# STM32U3C5 register map
File version: 1.0
CPU: CM33 r0p1, little endian, MPU, FPU, 4 interrupt priority bits
Registers are 32-bit, read-write, reset 0x0 unless marked. A register's access mark holds for its fields unless they carry their own. Offsets are from the block's base; [hi:lo] are bit positions; {n}, {i} and the like mark numbered series.

## SYSCFG — SYSCFG register block
Base 0x40040400
Same registers: SEC_SYSCFG 0x50040400
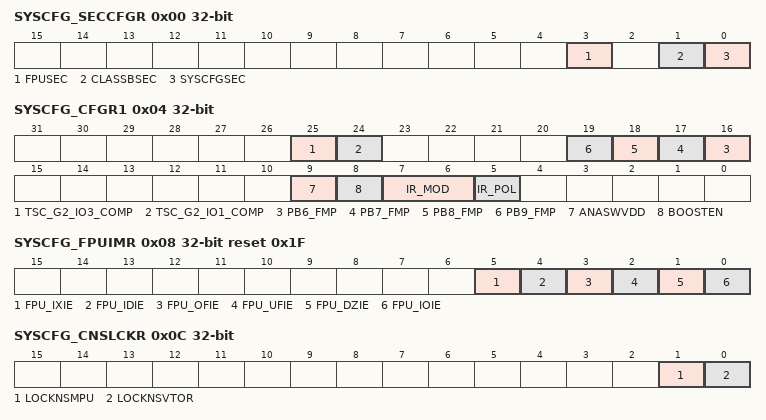
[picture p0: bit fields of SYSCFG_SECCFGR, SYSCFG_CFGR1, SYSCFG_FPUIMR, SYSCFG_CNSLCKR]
0x00 SYSCFG_SECCFGR — SYSCFG secure configuration register
  [3] FPUSEC — FPU security
    0=SYSCFG_FPUIMR can be read and written by secure and nonsecure access; 1=SYSCFG_FPUIMR can be read and written by secure access only
  [1] CLASSBSEC — Class B security
    0=SYSCFG_CFGR2 can be read and written by secure and nonsecure access; 1=SYSCFG_CFGR2 can be read and written by secure access only
  [0] SYSCFGSEC — Security of SYSCFG clock control, memory erase status, and compensation cell registers
    0=SYSCFG configuration clock in RCC registers and SYSCFG_CCCSR, SYSCFG_CCVR, and SYSCFG_CCCR can be read and written by secure and nonsecure access; 1=SYSCFG configuration clock in RCC registers and SYSCFG_CCCSR, SYSCFG_CCVR, and SYSCFG_CCCR can be read and written by secure access only
0x04 SYSCFG_CFGR1 — SYSCFG configuration register 1
  [25] TSC_G2_IO3_COMP — Comparator mode for G2_IO3 on PB6
    0=Normal mode: TSC_G2_IO3 detection is done using PB6 Vless thansub>IHless than/sub> I/O threshold; 1=Comparator mode: TSC_G2_IO3 detection is done using COMP2_INM threshold
  [24] TSC_G2_IO1_COMP — Comparator mode for G2_IO1 on PB4
    0=Normal mode: TSC_G2_IO1 detection is done using PB4 Vless thansub>IHless than/sub> I/O threshold; 1=Comparator mode: TSC_G2_IO1 detection is done using COMP2_INM threshold
  [n+10] PB{n}_FMP (n=6..9) — Fast-mode Plus driving capability activation on PBi
    0=PBi pin operates in standard mode; 1=Fm+ mode is enabled on PBi pin and the speed control is bypassed
  [9] ANASWVDD — GPIO analog switch control voltage selection
    0=I/O analog switches are supplied by Vless thansub>DDAless than/sub> or booster when booster is ON; 1=I/O analog switches are supplied by Vless thansub>DDless than/sub>
  [8] BOOSTEN — I/O analog switch voltage booster enable
    0=I/O analog switches are supplied by Vless thansub>DDAless than/sub> voltage; 1=I/O analog switches are supplied by a dedicated voltage booster (supplied by Vless thansub>DDless than/sub>)
  [7:6] IR_MOD — IR modulation envelope signal selection
    0=TIM16; 1=USART1; 2=UART4
  [5] IR_POL — IR output polarity selection
    0=Output of IRTIM (IR_OUT) is not inverted; 1=Output of IRTIM (IR_OUT) is inverted
0x08 SYSCFG_FPUIMR reset 0x1F — SYSCFG FPU interrupt mask register
  [all] fields
    0=Interrupt disabled; 1=Interrupt enabled
  [5] FPU_IXIE — Floating point unit interrupt enable bit - inexact
  [4] FPU_IDIE — Floating point unit interrupt enable bit - input denormal
  [3] FPU_OFIE — Floating point unit interrupt enable bit - overflow
  [2] FPU_UFIE — Floating point unit interrupt enable bit - underflow
  [1] FPU_DZIE — Floating point unit interrupt enable bit - divide-by-zero
  [0] FPU_IOIE — Floating point unit interrupt enable bit - invalid operation
0x0C SYSCFG_CNSLCKR — SYSCFG CPU nonsecure lock register
  [1] LOCKNSMPU — Nonsecure MPU registers lock
    0=Nonsecure MPU register write enabled; 1=Nonsecure MPU register write disabled
  [0] LOCKNSVTOR — VTOR_NS register lock
    0=VTOR_NS register write enabled; 1=VTOR_NS register write disabled
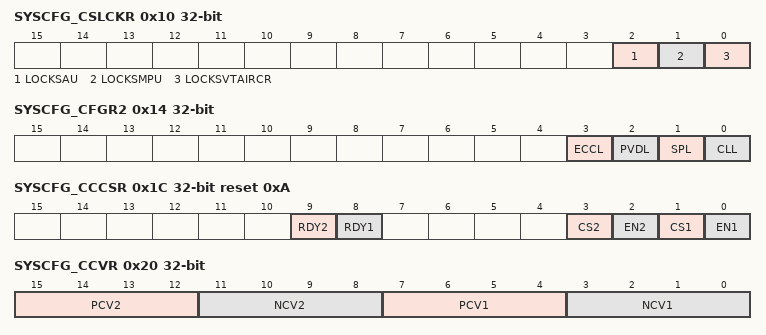
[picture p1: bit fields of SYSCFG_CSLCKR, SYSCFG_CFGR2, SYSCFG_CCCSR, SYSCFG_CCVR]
0x10 SYSCFG_CSLCKR — SYSCFG CPU secure lock register
  [2] LOCKSAU — SAU register lock
    0=SAU register write enabled; 1=SAU register write disabled
  [1] LOCKSMPU — Secure MPU registers lock
    0=Secure MPU register writes enabled; 1=Secure MPU register writes disabled
  [0] LOCKSVTAIRCR — VTOR_S register and AIRCR register bits lock
    0=VTOR_S register PRIS and BFHFNMINS bits in AIRCR register write enabled; 1=VTOR_S register PRIS and BFHFNMINS bits in AIRCR register write disabled
0x14 SYSCFG_CFGR2 — SYSCFG configuration register 2
  [3] ECCL — ECC lock
    0=ECC double error disconnected from TIM1/8/15/16/17 break input; 1=ECC double error connected to TIM1/8/15/16/17 break input
  [2] PVDL — PVD lock enable bit
    0=PVD interrupt disconnected from TIM1/8/15/16/17 break input; 1=PVD interrupt connected to TIM1/8/15/16/17 break input
  [1] SPL — SRAM2 parity bit
    0=SRAM double error disconnected from TIM1/8/15/16/17 break inputs; 1=SRAM double error connected to TIM1/8/15/16/17 break inputs
  [0] CLL — Cortex-M33 LOCKUP (HardFault) output enable
    0=Cortex-M33 LOCKUP output disconnected from TIM1/8/15/16/17 break inputs; 1=Cortex-M33 LOCKUP output connected to TIM1/8/15/16/17 break inputs
0x1C SYSCFG_CCCSR reset 0xA — SYSCFG compensation cell control/status register
  [9] RDY2 ro — VDDIO2 I/O compensation cell ready flag
    0=VDDIO2 I/O compensation cell not ready; 1=VDDIO2 I/O compensation cell ready
  [8] RDY1 ro — VDD I/O compensation cell ready flag
    0=VDD I/O compensation cell not ready; 1=VDD I/O compensation cell ready
  [3] CS2 — VDDIO2 I/O code selection
    0=VDDIO2 I/O code from the cell (available in SYSCFG_CCVR); 1=VDDIO2 I/O code from SYSCFG_CCCR
  [2] EN2 — VDDIO2 I/O compensation cell enable
    0=VDDIO2 I/O compensation cell disabled; 1=VDDIO2 I/O compensation cell enabled
  [1] CS1 — VDD I/O code selection
    0=VDD I/O code from the cell (available in the SYSCFG_CCVR); 1=VDD I/O code from the SYSCFG compensation cell code register (SYSCFG_CCCR)
  [0] EN1 — VDD I/O compensation cell enable
    0=VDD I/O compensation cell disabled; 1=VDD I/O compensation cell enabled
0x20 SYSCFG_CCVR ro — SYSCFG compensation cell value register
  [15:12] PCV2 — PMOS compensation value of the I/Os supplied by Vless thansub>DDIO2less than/sub>
  [11:8] NCV2 — NMOS compensation value of the I/Os supplied by Vless thansub>DDIO2less than/sub>
  [7:4] PCV1 — PMOS compensation value of the I/Os supplied by Vless thansub>DDless than/sub>
  [3:0] NCV1 — NMOS compensation value of the I/Os supplied by Vless thansub>DDless than/sub>
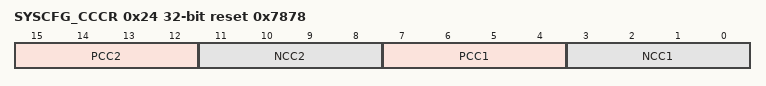
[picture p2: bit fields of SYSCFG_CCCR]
0x24 SYSCFG_CCCR reset 0x7878 — SYSCFG compensation cell code register
  [15:12] PCC2 — PMOS compensation code of the I/Os supplied by Vless thansub>DDIO2less than/sub>
  [11:8] NCC2 — NMOS compensation code of the I/Os supplied by Vless thansub>DDIO2less than/sub>
  [7:4] PCC1 — PMOS compensation code of the I/Os supplied by Vless thansub>DDless than/sub>
  [3:0] NCC1 — NMOS compensation code of the I/Os supplied by Vless thansub>DDless than/sub>
0x2C SYSCFG_RSSCMDR — SYSCFG RSS command register
  [15:0] RSSCMD — RSS commands
